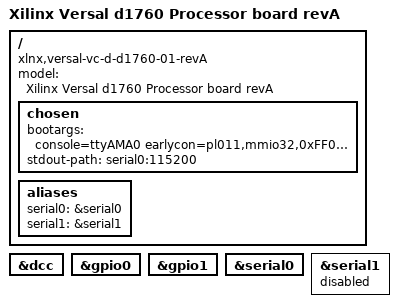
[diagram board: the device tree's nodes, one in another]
// SPDX-License-Identifier: GPL-2.0
/*
 * dts file for Xilinx Versal
 *
 * (C) Copyright 2019, Xilinx, Inc.
 *
 * Michal Simek <michal.simek@xilinx.com>
 */


/ {
	compatible = "xlnx,versal-vc-d-d1760-01-revA",
		     "xlnx,versal-vc-d-d1760-01",
		     "xlnx,versal-vc-d-d1760", "xlnx,versal";
	model = "Xilinx Versal d1760 Processor board revA"; /* xbb2525/v350 */

	chosen {
		bootargs = "console=ttyAMA0 earlycon=pl011,mmio32,0xFF010000,115200n8 clk_ignore_unused";
		stdout-path = "serial0:115200";
	};

	aliases {
		serial0 = &serial0;
		serial1 = &serial1;
	};
};

&dcc {
	status = "okay";
};

&gpio0 {
	status = "okay";
};

&gpio1 {
	status = "okay";
};

&serial0 {
	status = "okay";
};

&serial1 {
	status = "disabled"; /* communication with MSP432 */
};
